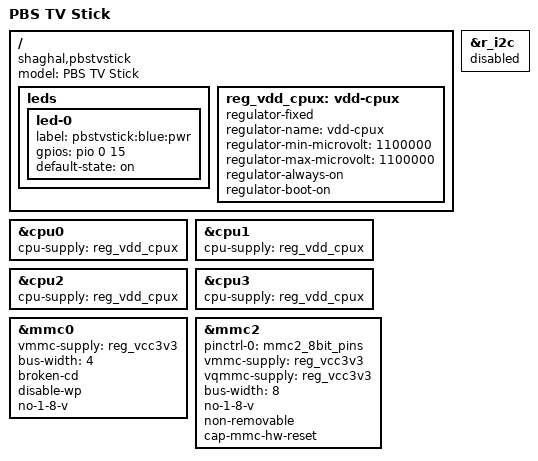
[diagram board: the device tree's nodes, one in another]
// SPDX-License-Identifier: (GPL-2.0+ OR MIT)
/*
 * Copyright (C) 2026
 */

#include "sun50i-h5-orangepi-prime.dts"

/delete-node/ &reg_vdd_cpux;

/ {
	model = "PBS TV Stick";
	compatible = "shaghal,pbstvstick", "allwinner,sun50i-h5";

	leds {
		led-0 {
			label = "pbstvstick:blue:pwr";
			gpios = <&pio 0 15 GPIO_ACTIVE_HIGH>;
			default-state = "on";
		};
	};

	reg_vdd_cpux: vdd-cpux {
		compatible = "regulator-fixed";
		regulator-name = "vdd-cpux";
		regulator-min-microvolt = <1100000>;
		regulator-max-microvolt = <1100000>;
		regulator-always-on;
		regulator-boot-on;
	};
};

&cpu0 {
	cpu-supply = <&reg_vdd_cpux>;
};

&cpu1 {
	cpu-supply = <&reg_vdd_cpux>;
};

&cpu2 {
	cpu-supply = <&reg_vdd_cpux>;
};

&cpu3 {
	cpu-supply = <&reg_vdd_cpux>;
};

&r_i2c {
	status = "disabled";
};

&mmc0 {
	vmmc-supply = <&reg_vcc3v3>;
	bus-width = <4>;
	/delete-property/ cd-gpios;
	broken-cd;
	disable-wp;
	no-1-8-v;
	status = "okay";
};

&mmc2 {
	pinctrl-names = "default";
	pinctrl-0 = <&mmc2_8bit_pins>;
	vmmc-supply = <&reg_vcc3v3>;
	vqmmc-supply = <&reg_vcc3v3>;
	bus-width = <8>;
	no-1-8-v;
	non-removable;
	cap-mmc-hw-reset;
	status = "okay";
};
